# altera_avalon_jtag_uart register map
Registers are 32-bit, read-write, reset 0x0 unless marked. A register's access mark holds for its fields unless they carry their own. Offsets are from the block's base; lines under a group give offsets from that group; [hi:lo] are bit positions; {n}, {i} and the like mark numbered series; 'fields as' and 'values as' point back to an identical list; <NAME> marks a mode.

## Memory map
0x00000000 altera_avalon_jtag_uart size 0x8

## altera_avalon_jtag_uart
Base 0x00000000
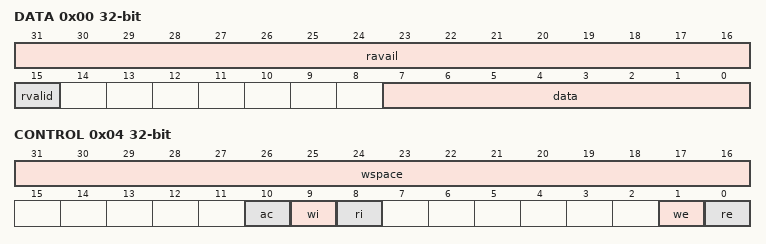
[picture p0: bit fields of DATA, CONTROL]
0x00 DATA — Embedded software accesses the read and write FIFOs via the data register. A read from the data register returns the first character from the FIFO (if one is available) in the DATA field. Reading also returns information about the number of characters remaining in the FIFO in the RAVAIL field. A write to the data register stores the value of the DATA field in the write FIFO. If the write FIFO is full, the character is lost.
  [31:16] ravail ro — The number of characters remaining in the read FIFO (after the current read).
  [15] rvalid ro — Indicates whether the DATA field is valid. If RVALID=1, the DATA field is valid, otherwise DATA is undefined.
  [7:0] data — The value to transfer to/from the JTAG core. When writing, the DATA field holds a character to be written to the write FIFO. When reading, the DATA field holds a character read from the read FIFO.
0x04 CONTROL — Embedded software controls the JTAG UART core's interrupt generation and reads status information via the control register. A read from the control register returns the status of the read and write FIFOs. Writes to the register can be used to enable/disable interrupts, or clear the AC bit.
  [31:16] wspace ro — The number of spaces available in the write FIFO
  [10] ac — Indicates that there has been JTAG activity since the bit was cleared. Writing 1 to AC clears it to 0.
  [9] wi ro — Indicates that the write interrupt is pending.
  [8] ri ro — Indicates that the read interrupt is pending.
  [1] we — Interrupt-enable bit for write interrupts
  [0] re — Interrupt-enable bit for read interrupts.
